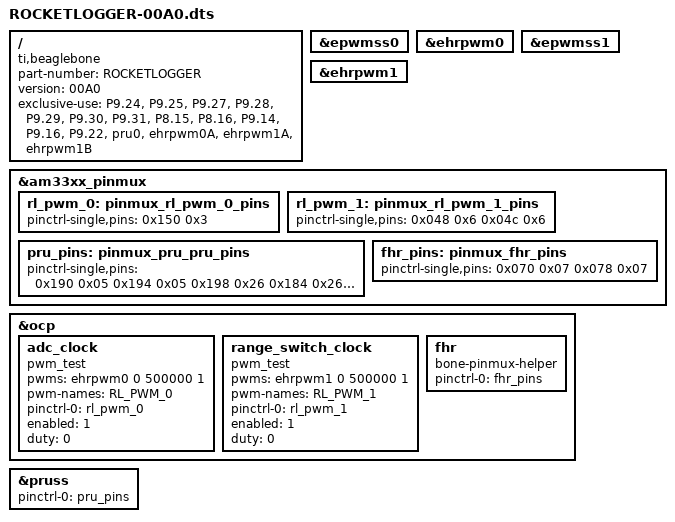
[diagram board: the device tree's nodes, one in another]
/dts-v1/;
/plugin/;

/ {
	compatible = "ti,beaglebone", "ti,beaglebone-green", "ti,beaglebone-black";

	/* identification */
	part-number = "ROCKETLOGGER";
	version = "00A0";

	/* state the resources this cape uses */
	exclusive-use =
		
		"P9.24",	/* PRU pins */
		"P9.25",
		"P9.27",
		"P9.28",
		"P9.29",
		"P9.30",
		"P9.31",
		"P8.15",
		"P8.16",
		
		"P9.14",	/* PWM pins */
		"P9.16",
		"P9.22",
		
		
		"pru0",		/* Hardware */
		"ehrpwm0A",
		"ehrpwm1A",
		"ehrpwm1B";
	
	/* Enable EHRPWM0 and EHRPWM1 */
	fragment@0 {
		target = <&epwmss0>;
		__overlay__ {
			status = "okay";
		};
	};

	fragment@1 {
		target = <&ehrpwm0>;
		__overlay__ {
			status = "okay";
		};
	};
	
	fragment@2 {
		target = <&epwmss1>;
		__overlay__ {
			status = "okay";
		};
	};

	fragment@3 {
		target = <&ehrpwm1>;
		__overlay__ {
			status = "okay";
		};
	};

	/* Set pin muxes */
	
	// ehrpwm0_pins
	fragment@4 {
		target = <&am33xx_pinmux>;
		__overlay__ {
			rl_pwm_0: pinmux_rl_pwm_0_pins {
				pinctrl-single,pins = <
					0x150  0x3
				>;
			};
		};
	};
	
	// ehrpwm1_pins
	fragment@5 {
		target = <&am33xx_pinmux>;
		__overlay__ {
			rl_pwm_1: pinmux_rl_pwm_1_pins {
				pinctrl-single,pins = <
					0x048  0x6
					0x04c  0x6
				>;
			};
		};
	};
	
	// pru_pins
	fragment@6 {  
		target = <&am33xx_pinmux>;  
		__overlay__ {  
		  pru_pins: pinmux_pru_pru_pins {  
		   pinctrl-single,pins = < 
			 0x190 0x05 // SCLK
			 0x194 0x05 // MOSI
			 0x198 0x26 // MISO0
			 0x184 0x26 // MISO1
			 0x19C 0x05 // CS0
			 0x1A4 0x05 // CS1
			 0x1AC 0x05 // START
			 0x038 0x36 // DR0
			 0x03C 0x36 // DR1
		   >;  
		  };  
		};  
	};  
	
	// force_high_range_pins
	fragment@7 {
        target = <&am33xx_pinmux>;
        __overlay__ {
            fhr_pins: pinmux_fhr_pins {
                pinctrl-single,pins = <
					0x070 0x07
					0x078 0x07
				>;
            };
        };
    };
	
	/* Apply pins to EHRPWM-Modules */
	fragment@8 {
		target = <&ocp>;
		__overlay__ {
			adc_clock {
				compatible	= "pwm_test";
				pwms 		= <&ehrpwm0 0 500000 1>;
				pwm-names 	= "RL_PWM_0";
			    pinctrl-names	= "default";
			    pinctrl-0	= <&rl_pwm_0>;
				enabled		= <1>;
				duty		= <0>;
				status 		= "okay";
			};
		};
	};

	fragment@9 {
		target = <&ocp>;
		__overlay__ {
			range_switch_clock {
				compatible	= "pwm_test";
				pwms 		= <&ehrpwm1 0 500000 1>;
				pwm-names 	= "RL_PWM_1";
			    pinctrl-names	= "default";
			    pinctrl-0	= <&rl_pwm_1>;
				enabled		= <1>;
				duty		= <0>;
				status 		= "okay";
			};
		};
	};
	
	fragment@10 {  
		target = <&pruss>;  
		__overlay__ {  
			status = "okay";  
			pinctrl-names = "default";  
			pinctrl-0 = <&pru_pins>;  
		};  
	}; 
   
	fragment@11 {
		target = <&ocp>;
		__overlay__ {
			fhr {
				compatible = "bone-pinmux-helper";
				pinctrl-names = "default";
				pinctrl-0 = <&fhr_pins>;
				status = "okay";
            };
        };
    };
};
